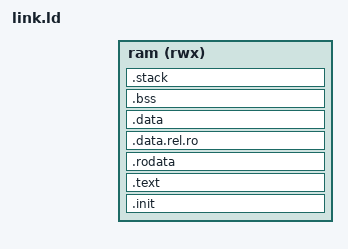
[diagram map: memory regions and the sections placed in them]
/*
 * SPDX-License-Identifier: BSD-3-Clause
 *
 * Copyright © 2019 Keith Packard
 *
 * Redistribution and use in source and binary forms, with or without
 * modification, are permitted provided that the following conditions
 * are met:
 *
 * 1. Redistributions of source code must retain the above copyright
 *    notice, this list of conditions and the following disclaimer.
 *
 * 2. Redistributions in binary form must reproduce the above
 *    copyright notice, this list of conditions and the following
 *    disclaimer in the documentation and/or other materials provided
 *    with the distribution.
 *
 * 3. Neither the name of the copyright holder nor the names of its
 *    contributors may be used to endorse or promote products derived
 *    from this software without specific prior written permission.
 *
 * THIS SOFTWARE IS PROVIDED BY THE COPYRIGHT HOLDERS AND CONTRIBUTORS
 * "AS IS" AND ANY EXPRESS OR IMPLIED WARRANTIES, INCLUDING, BUT NOT
 * LIMITED TO, THE IMPLIED WARRANTIES OF MERCHANTABILITY AND FITNESS
 * FOR A PARTICULAR PURPOSE ARE DISCLAIMED. IN NO EVENT SHALL THE
 * COPYRIGHT HOLDER OR CONTRIBUTORS BE LIABLE FOR ANY DIRECT,
 * INDIRECT, INCIDENTAL, SPECIAL, EXEMPLARY, OR CONSEQUENTIAL DAMAGES
 * (INCLUDING, BUT NOT LIMITED TO, PROCUREMENT OF SUBSTITUTE GOODS OR
 * SERVICES; LOSS OF USE, DATA, OR PROFITS; OR BUSINESS INTERRUPTION)
 * HOWEVER CAUSED AND ON ANY THEORY OF LIABILITY, WHETHER IN CONTRACT,
 * STRICT LIABILITY, OR TORT (INCLUDING NEGLIGENCE OR OTHERWISE)
 * ARISING IN ANY WAY OUT OF THE USE OF THIS SOFTWARE, EVEN IF ADVISED
 * OF THE POSSIBILITY OF SUCH DAMAGE.
 */

ENTRY(_start)

/*
 * These values should be provided by the application. We'll include
 * some phony values here to make things link for testing
 */

MEMORY
{
	ram (rwx) :
		ORIGIN = DEFINED(__ram) ? __ram : 0x00000000,
		LENGTH = DEFINED(__ram_size) ? __ram_size : 0x00002000
}

PHDRS
{
	ram PT_LOAD;
}

SECTIONS
{
	PROVIDE(__stack = ORIGIN(ram) + LENGTH(ram));

	.init : {
		KEEP (*(.text.init.enter))
		KEEP (*(.data.init.enter))
		KEEP (*(SORT_BY_NAME(.init) SORT_BY_NAME(.init.*)))
	} >ram AT>ram :ram

	PROVIDE(__img_start = ADDR(.init));

	.text : {

		/* code */
		*(.text.unlikely .text.unlikely.*)
		*(.text.startup .text.startup.*)
		*(.text .text.* .opd .opd.*)
		*(.gnu.linkonce.t.*)
		KEEP (*(.fini .fini.*))
		__text_end = .;

		PROVIDE (__etext = __text_end);
		PROVIDE (_etext = __text_end);
		PROVIDE (etext = __text_end);

		/* Need to pre-align so that the symbols come after padding */
		. = ALIGN(8);
	} >ram AT>ram :ram

	.rodata : {

		/* read-only data */
		*(.rdata)
		*(.rodata .rodata.*)
		*(.gnu.linkonce.r.*)

		*(.srodata.cst16)
		*(.srodata.cst8)
		*(.srodata.cst4)
		*(.srodata.cst2)
		*(.srodata .srodata.*)

	} >ram AT>ram :ram

	.data.rel.ro : {

		/* data that needs relocating */
		*(.data.rel.ro .data.rel.ro.*)

	} >ram AT>ram :ram

	.data :  ALIGN_WITH_INPUT  {
		*(.data .data.*)
		*(.gnu.linkonce.d.*)

		/* Need to pre-align so that the symbols come after padding */
		. = ALIGN(8);

		PROVIDE( __global_pointer$ = . + 0x800 );
		PROVIDE( _gp = . + 0x8000);
		*(.sdata .sdata.* .sdata2.*)
		*(.gnu.linkonce.s.*)
		PROVIDE(__data_end = .);

		. = ALIGN(8);
	} >ram AT>ram :ram

	PROVIDE(__data_start = ADDR(.data));
	PROVIDE(__data_source = LOADADDR(.data));

	PROVIDE( __edata = __data_end );
	PROVIDE( _edata = __data_end );
	PROVIDE( edata = __data_end );
	PROVIDE( __data_size = __data_end - __data_start );

	PROVIDE(__img_end = __data_end);
	PROVIDE(__img_size = __img__end - __img_start);

	.bss (NOLOAD) : {
		*(.sbss*)
		*(.gnu.linkonce.sb.*)
		*(.bss .bss.*)
		*(.gnu.linkonce.b.*)
		*(COMMON)

		/* Align the heap */
		. = ALIGN(8);
		__bss_end = .;
	} >ram AT>ram :ram

	PROVIDE( __bss_start = ADDR(.bss) );
	PROVIDE( __end = __bss_end );
	_end = __bss_end;
	PROVIDE( end = __bss_end );
	PROVIDE( __bss_size = __bss_end - __bss_start );

	/* Define a stack region to make sure it fits in memory */
	.stack (NOLOAD) : {
		. += (DEFINED(__stack_size) ? __stack_size : 0x00001000);
	} >ram :ram

	/* Throw away C++ exception handling information */

	

	/DISCARD/ : {
		*(.note .note.*)
		*(.eh_frame .eh_frame.*)
		*(.ARM.extab* .gnu.linkonce.armextab.*)
		*(.ARM.exidx*)
	}

	

	/* Stabs debugging sections.  */
	.stab          0 : { *(.stab) }
	.stabstr       0 : { *(.stabstr) }
	.stab.excl     0 : { *(.stab.excl) }
	.stab.exclstr  0 : { *(.stab.exclstr) }
	.stab.index    0 : { *(.stab.index) }
	.stab.indexstr 0 : { *(.stab.indexstr) }
	.comment       0 : { *(.comment) }
	.gnu.build.attributes : { *(.gnu.build.attributes .gnu.build.attributes.*) }
	/* DWARF debug sections.
	   Symbols in the DWARF debugging sections are relative to the beginning
	   of the section so we begin them at 0.  */
	/* DWARF 1.  */
	.debug          0 : { *(.debug) }
	.line           0 : { *(.line) }
	/* GNU DWARF 1 extensions.  */
	.debug_srcinfo  0 : { *(.debug_srcinfo) }
	.debug_sfnames  0 : { *(.debug_sfnames) }
	/* DWARF 1.1 and DWARF 2.  */
	.debug_aranges  0 : { *(.debug_aranges) }
	.debug_pubnames 0 : { *(.debug_pubnames) }
	/* DWARF 2.  */
	.debug_info     0 : { *(.debug_info .gnu.linkonce.wi.*) }
	.debug_abbrev   0 : { *(.debug_abbrev) }
	.debug_line     0 : { *(.debug_line .debug_line.* .debug_line_end) }
	.debug_frame    0 : { *(.debug_frame) }
	.debug_str      0 : { *(.debug_str) }
	.debug_loc      0 : { *(.debug_loc) }
	.debug_macinfo  0 : { *(.debug_macinfo) }
	/* SGI/MIPS DWARF 2 extensions.  */
	.debug_weaknames 0 : { *(.debug_weaknames) }
	.debug_funcnames 0 : { *(.debug_funcnames) }
	.debug_typenames 0 : { *(.debug_typenames) }
	.debug_varnames  0 : { *(.debug_varnames) }
	/* DWARF 3.  */
	.debug_pubtypes 0 : { *(.debug_pubtypes) }
	.debug_ranges   0 : { *(.debug_ranges) }
	/* DWARF 5.  */
	.debug_addr     0 : { *(.debug_addr) }
	.debug_line_str 0 : { *(.debug_line_str) }
	.debug_loclists 0 : { *(.debug_loclists) }
	.debug_macro    0 : { *(.debug_macro) }
	.debug_names    0 : { *(.debug_names) }
	.debug_rnglists 0 : { *(.debug_rnglists) }
	.debug_str_offsets 0 : { *(.debug_str_offsets) }
	.debug_sup      0 : { *(.debug_sup) }
	.gnu.attributes 0 : { KEEP (*(.gnu.attributes)) }
}
